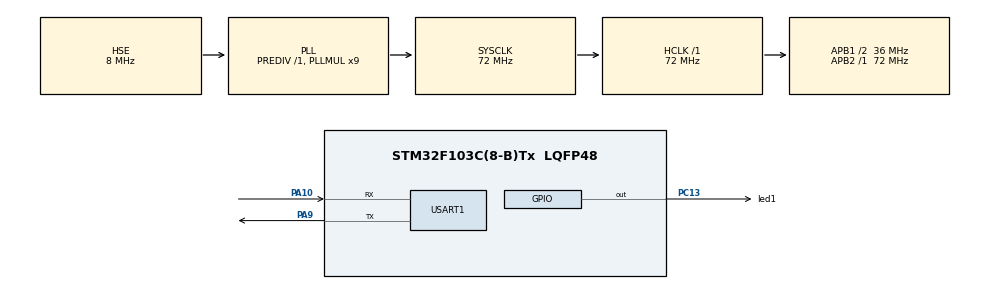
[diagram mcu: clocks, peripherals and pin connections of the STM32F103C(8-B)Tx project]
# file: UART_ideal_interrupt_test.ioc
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Mcu.Family=STM32F1
RCC.PLLSourceVirtual=RCC_PLLSOURCE_HSE
Dma.USART1_TX.1.Instance=DMA1_Channel4
NVIC.DMA1_Channel5_IRQn=true\:0\:0\:false\:false\:true\:false\:true
PD1-OSC_OUT.Mode=HSE-External-Oscillator
Dma.USART1_RX.0.PeriphDataAlignment=DMA_PDATAALIGN_BYTE
PA10.Mode=Asynchronous
Dma.USART1_TX.1.MemInc=DMA_MINC_ENABLE
PC13-TAMPER-RTC.Signal=GPIO_Output
PD0-OSC_IN.Signal=RCC_OSC_IN
RCC.APB1CLKDivider=RCC_HCLK_DIV2
RCC.SYSCLKSource=RCC_SYSCLKSOURCE_PLLCLK
ProjectManager.StackSize=0x400
PD1-OSC_OUT.Signal=RCC_OSC_OUT
PA13.Signal=SYS_JTMS-SWDIO
PA9.Mode=Asynchronous
ProjectManager.TargetToolchain=STM32CubeIDE
Dma.USART1_RX.0.Direction=DMA_PERIPH_TO_MEMORY
RCC.HCLKFreq_Value=72000000
RCC.APB2TimFreq_Value=72000000
PA9.Signal=USART1_TX
RCC.USBFreq_Value=72000000
RCC.AHBFreq_Value=72000000
Dma.USART1_RX.0.PeriphInc=DMA_PINC_DISABLE
Dma.USART1_RX.0.Priority=DMA_PRIORITY_LOW
PD0-OSC_IN.Mode=HSE-External-Oscillator
Dma.USART1_TX.1.MemDataAlignment=DMA_MDATAALIGN_BYTE
board=custom
PC13-TAMPER-RTC.GPIO_Label=led1
RCC.PLLMUL=RCC_PLL_MUL9
RCC.APB2Freq_Value=72000000
PA14.Mode=Serial_Wire
Dma.USART1_RX.0.MemDataAlignment=DMA_MDATAALIGN_BYTE
Dma.USART1_RX.0.MemInc=DMA_MINC_ENABLE
PA13.Mode=Serial_Wire
Mcu.Name=STM32F103C(8-B)Tx
Dma.USART1_TX.1.PeriphDataAlignment=DMA_PDATAALIGN_BYTE
RCC.SYSCLKFreq_VALUE=72000000
Mcu.Package=LQFP48
Dma.USART1_TX.1.Mode=DMA_NORMAL
USART1.VirtualMode=VM_ASYNC
PA10.Signal=USART1_RX
PA14.Signal=SYS_JTCK-SWCLK
ProjectManager.HeapSize=0x200
Dma.USART1_TX.1.PeriphInc=DMA_PINC_DISABLE
NVIC.PriorityGroup=NVIC_PRIORITYGROUP_4
Dma.Request1=USART1_TX
RCC.APB1TimFreq_Value=72000000
Dma.USART1_RX.0.Mode=DMA_CIRCULAR
Dma.USART1_TX.1.Priority=DMA_PRIORITY_LOW
NVIC.DMA1_Channel4_IRQn=true\:0\:0\:false\:false\:true\:false\:true
NVIC.USART1_IRQn=true\:0\:0\:false\:false\:true\:true\:true
Dma.Request0=USART1_RX
RCC.APB1Freq_Value=36000000
Dma.USART1_RX.0.Instance=DMA1_Channel5
Dma.USART1_TX.1.Direction=DMA_MEMORY_TO_PERIPH

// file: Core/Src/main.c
/* USER CODE BEGIN Header */
/**
  ******************************************************************************
  * @file           : main.c
  * @brief          : Main program body
  ******************************************************************************
  * @attention
  *
  * <h2><center>&copy; Copyright (c) 2021 STMicroelectronics.
  * All rights reserved.</center></h2>
  *
  * This software component is licensed by ST under BSD 3-Clause license,
  * the "License"; You may not use this file except in compliance with the
  * License. You may obtain a copy of the License at:
  *                        opensource.org/licenses/BSD-3-Clause
  *
  ******************************************************************************
  */
/* USER CODE END Header */
#include "main.h"

/* USER CODE BEGIN Includes */
#include<stdio.h>
#include<string.h>
#include "S76s_command_ledblink.h"
/* USER CODE END Includes */

/* USER CODE BEGIN PD */
#define RX_BFR_SIZE 16
#define TX_BFR_SIZE 64

/* USER CODE END PD */

UART_HandleTypeDef huart1;
DMA_HandleTypeDef hdma_usart1_rx;
DMA_HandleTypeDef hdma_usart1_tx;

/* USER CODE BEGIN PV */
uint8_t RxRollover = 0;
uint8_t RxCounter = 0;
uint16_t RxBfrPos = 0;
uint8_t TxCounter = 0;
char TxBuffer[TX_BFR_SIZE];
uint8_t RxBuffer[RX_BFR_SIZE];

/* USER CODE END PV */

void SystemClock_Config(void);
static void MX_GPIO_Init(void);
static void MX_DMA_Init(void);
static void MX_USART1_UART_Init(void);

/* USER CODE BEGIN 0 */
void HAL_UART_RxCpltCallback(UART_HandleTypeDef *huart);
void HAL_UART_TxCpltCallback(UART_HandleTypeDef *huart);
/* USER CODE END 0 */

int main(void)
{

  /* MCU Configuration--------------------------------------------------------*/

  /* Reset of all peripherals, Initializes the Flash interface and the Systick. */
  HAL_Init();

  /* Configure the system clock */
  SystemClock_Config();

  /* Initialize all configured peripherals */
  MX_GPIO_Init();
  MX_DMA_Init();
  MX_USART1_UART_Init();
  /* USER CODE BEGIN 2 */
  __HAL_UART_ENABLE_IT(&huart1, UART_IT_IDLE);
    HAL_UART_Receive_DMA(&huart1, RxBuffer, RX_BFR_SIZE);
    HAL_GPIO_WritePin(led1_GPIO_Port, led1_Pin,GPIO_PIN_SET);

  /* USER CODE END 2 */

  /* Infinite loop */
  while (1)
  {

  }
}

void SystemClock_Config(void)
{
  RCC_OscInitTypeDef RCC_OscInitStruct = {0};
  RCC_ClkInitTypeDef RCC_ClkInitStruct = {0};

  /** Initializes the RCC Oscillators according to the specified parameters
  * in the RCC_OscInitTypeDef structure.
  */
  RCC_OscInitStruct.OscillatorType = RCC_OSCILLATORTYPE_HSE;
  RCC_OscInitStruct.HSEState = RCC_HSE_ON;
  RCC_OscInitStruct.HSEPredivValue = RCC_HSE_PREDIV_DIV1;
  RCC_OscInitStruct.HSIState = RCC_HSI_ON;
  RCC_OscInitStruct.PLL.PLLState = RCC_PLL_ON;
  RCC_OscInitStruct.PLL.PLLSource = RCC_PLLSOURCE_HSE;
  RCC_OscInitStruct.PLL.PLLMUL = RCC_PLL_MUL9;
  if (HAL_RCC_OscConfig(&RCC_OscInitStruct) != HAL_OK)
  {
    Error_Handler();
  }
  /** Initializes the CPU, AHB and APB buses clocks
  */
  RCC_ClkInitStruct.ClockType = RCC_CLOCKTYPE_HCLK|RCC_CLOCKTYPE_SYSCLK
                              |RCC_CLOCKTYPE_PCLK1|RCC_CLOCKTYPE_PCLK2;
  RCC_ClkInitStruct.SYSCLKSource = RCC_SYSCLKSOURCE_PLLCLK;
  RCC_ClkInitStruct.AHBCLKDivider = RCC_SYSCLK_DIV1;
  RCC_ClkInitStruct.APB1CLKDivider = RCC_HCLK_DIV2;
  RCC_ClkInitStruct.APB2CLKDivider = RCC_HCLK_DIV1;

  if (HAL_RCC_ClockConfig(&RCC_ClkInitStruct, FLASH_LATENCY_2) != HAL_OK)
  {
    Error_Handler();
  }
}

static void MX_USART1_UART_Init(void)
{

  huart1.Instance = USART1;
  huart1.Init.BaudRate = 115200;
  huart1.Init.WordLength = UART_WORDLENGTH_8B;
  huart1.Init.StopBits = UART_STOPBITS_1;
  huart1.Init.Parity = UART_PARITY_NONE;
  huart1.Init.Mode = UART_MODE_TX_RX;
  huart1.Init.HwFlowCtl = UART_HWCONTROL_NONE;
  huart1.Init.OverSampling = UART_OVERSAMPLING_16;
  if (HAL_UART_Init(&huart1) != HAL_OK)
  {
    Error_Handler();
  }

}

static void MX_DMA_Init(void)
{

  /* DMA controller clock enable */
  __HAL_RCC_DMA1_CLK_ENABLE();

  /* DMA interrupt init */
  /* DMA1_Channel4_IRQn interrupt configuration */
  HAL_NVIC_SetPriority(DMA1_Channel4_IRQn, 0, 0);
  HAL_NVIC_EnableIRQ(DMA1_Channel4_IRQn);
  /* DMA1_Channel5_IRQn interrupt configuration */
  HAL_NVIC_SetPriority(DMA1_Channel5_IRQn, 0, 0);
  HAL_NVIC_EnableIRQ(DMA1_Channel5_IRQn);

}

static void MX_GPIO_Init(void)
{
  GPIO_InitTypeDef GPIO_InitStruct = {0};

  /* GPIO Ports Clock Enable */
  __HAL_RCC_GPIOC_CLK_ENABLE();
  __HAL_RCC_GPIOD_CLK_ENABLE();
  __HAL_RCC_GPIOA_CLK_ENABLE();

  /*Configure GPIO pin Output Level */
  HAL_GPIO_WritePin(led1_GPIO_Port, led1_Pin, GPIO_PIN_RESET);

  /*Configure GPIO pin : led1_Pin */
  GPIO_InitStruct.Pin = led1_Pin;
  GPIO_InitStruct.Mode = GPIO_MODE_OUTPUT_PP;
  GPIO_InitStruct.Pull = GPIO_NOPULL;
  GPIO_InitStruct.Speed = GPIO_SPEED_FREQ_LOW;
  HAL_GPIO_Init(led1_GPIO_Port, &GPIO_InitStruct);

}

/* USER CODE BEGIN 4 */
void HAL_UART_RxCpltCallback(UART_HandleTypeDef *huart) {
	// UART Rx Complete Callback;
	// Rx Complete is called by: DMA (automatically), if it rolls over
	// and when an IDLE Interrupt occurs
	// DMA Interrupt allays occurs BEFORE the idle interrupt can be fired because
	// idle detection needs at least one UART clock to detect the bus is idle. So
	// in the case, that the transmission length is one full buffer length
	// and the start buffer pointer is at 0, it will be also 0 at the end of the
	// transmission. In this case the DMA rollover will increment the RxRollover
	// variable first and len will not be zero.
	if(__HAL_UART_GET_FLAG(huart, UART_FLAG_IDLE)) {									// Check if it is an "Idle Interrupt"
		__HAL_UART_CLEAR_IDLEFLAG(&huart1);												// clear the interrupt
		RxCounter++;																	// increment the Rx Counter

		uint8_t TxSize = 0;
		uint16_t start = RxBfrPos;														// Rx bytes start position (=last buffer position)
		RxBfrPos = RX_BFR_SIZE - (uint16_t)huart->hdmarx->Instance->CNDTR;				// determine actual buffer position
		uint16_t len = RX_BFR_SIZE;														// init len with max. size

		if(RxRollover < 2)  {
			if(RxRollover) {															// rolled over once
				if(RxBfrPos <= start) len = RxBfrPos + RX_BFR_SIZE - start;				// no bytes overwritten
				else len = RX_BFR_SIZE + 1;												// bytes overwritten error
			} else {
				len = RxBfrPos - start;													// no bytes overwritten
			}
		} else {
			len = RX_BFR_SIZE + 2;														// dual rollover error
		}

		if(len && (len <= RX_BFR_SIZE)) {
			// create response message
			//sprintf(TxBuffer, "ACK RxC:%d S:%d L:%d RO:%d RXp:%d >>", RxCounter, start, len, RxRollover, RxBfrPos);
			sprintf(TxBuffer,(char *)TransmitFormatter(1));
			TxSize = strlen(TxBuffer);
			// add received bytes to TxBuffer
			uint8_t i;
			for(i = 0; i < len; i++) *(TxBuffer + TxSize + i) = *(RxBuffer + ((start + i) % RX_BFR_SIZE));
			TxSize += i;
		} else {
			// buffer overflow error:
			sprintf(TxBuffer, "NAK RX BUFFER OVERFLOW ERROR %d\r\n", (len - RX_BFR_SIZE));
			TxSize = strlen(TxBuffer);
		}

		HAL_UART_Transmit_DMA(&huart1, (uint8_t*)TxBuffer, TxSize);						// send a response

		RxRollover = 0;																	// reset the Rollover variable
	} else {
		// no idle flag? --> DMA rollover occurred
		RxRollover++;		// increment Rollover Counter
	}
}

void HAL_UART_TxCpltCallback(UART_HandleTypeDef *huart) {
	// UART Tx Complete Callback;
	TxCounter++;
	HAL_GPIO_TogglePin(led1_GPIO_Port, led1_Pin);
}

/* USER CODE END 4 */

void Error_Handler(void)
{
  __disable_irq();
  while (1)
  {
  }
}

/************************ (C) COPYRIGHT STMicroelectronics *****END OF FILE****/
